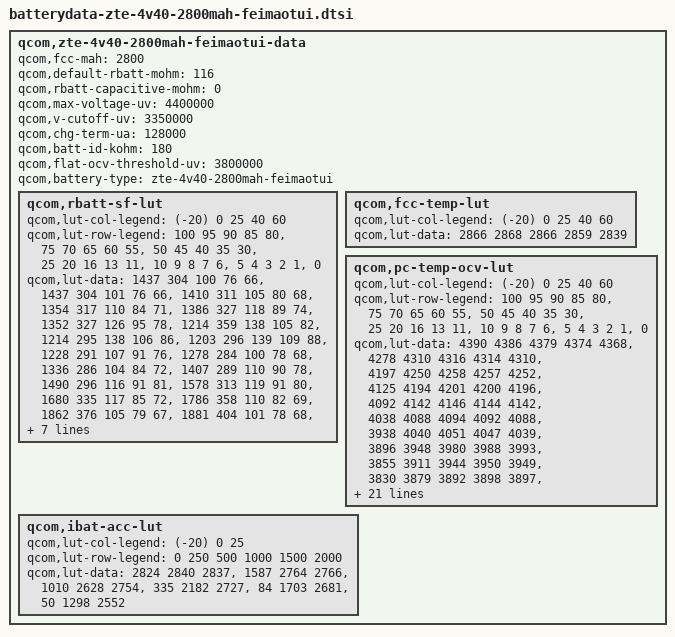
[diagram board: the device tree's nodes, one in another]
/* Copyright (c) 2014, The Linux Foundation. All rights reserved.
 *
 * This program is free software; you can redistribute it and/or modify
 * it under the terms of the GNU General Public License version 2 and
 * only version 2 as published by the Free Software Foundation.
 *
 * This program is distributed in the hope that it will be useful,
 * but WITHOUT ANY WARRANTY; without even the implied warranty of
 * MERCHANTABILITY or FITNESS FOR A PARTICULAR PURPOSE.  See the
 * GNU General Public License for more details.
 */
 qcom,zte-4v40-2800mah-feimaotui-data {
	qcom,fcc-mah = <2800>;
	qcom,default-rbatt-mohm = <116>;
	qcom,rbatt-capacitive-mohm = <0>;
	qcom,max-voltage-uv = <4400000>;
	qcom,v-cutoff-uv = <3350000>;
	qcom,chg-term-ua = <128000>;
	qcom,batt-id-kohm = <180>;
	qcom,flat-ocv-threshold-uv = <3800000>;
	qcom,battery-type = "zte-4v40-2800mah-feimaotui";
 
	qcom,rbatt-sf-lut {
		qcom,lut-col-legend = <(-20) 0 25 40 60>;
		qcom,lut-row-legend = <100 95 90 85 80>,
				<75 70 65 60 55>,
				<50 45 40 35 30>,
				<25 20 16 13 11>,
				<10 9 8 7 6>,
				<5 4 3 2 1>,
				<0>;
		qcom,lut-data = <1437 304 100 76 66>,
				<1437 304 101 76 66>,
				<1410 311 105 80 68>,
				<1354 317 110 84 71>,
				<1386 327 118 89 74>,
				<1352 327 126 95 78>,
				<1214 359 138 105 82>,
				<1214 295 138 106 86>,
				<1203 296 139 109 88>,
				<1228 291 107 91 76>,
				<1278 284 100 78 68>,
				<1336 286 104 84 72>,
				<1407 289 110 90 78>,
				<1490 296 116 91 81>,
				<1578 313 119 91 80>,
				<1680 335 117 85 72>,
				<1786 358 110 82 69>,
				<1862 376 105 79 67>,
				<1881 404 101 78 68>,
				<1815 409 107 84 72>,
				<1853 424 112 88 74>,
				<1873 445 119 91 76>,
				<1936 464 123 95 77>,
				<1989 483 126 96 75>,
				<2133 498 122 89 72>,
				<2417 509 116 87 74>,
				<2732 528 120 91 79>,
				<3215 565 128 100 84>,
				<4009 618 146 109 90>,
				<6202 741 192 133 116>,
				<36781 16819 10403 1488 6787>;
	};

	qcom,fcc-temp-lut {
		qcom,lut-col-legend = <(-20) 0 25 40 60>;
		qcom,lut-data = <2866 2868 2866 2859 2839>;
	};

	qcom,pc-temp-ocv-lut {
		qcom,lut-col-legend = <(-20) 0 25 40 60>;
		qcom,lut-row-legend = <100 95 90 85 80>,
				<75 70 65 60 55>,
				<50 45 40 35 30>,
				<25 20 16 13 11>,
				<10 9 8 7 6>,
				<5 4 3 2 1>,
				<0>;
		qcom,lut-data = <4390 4386 4379 4374 4368>,
				<4278 4310 4316 4314 4310>,
				<4197 4250 4258 4257 4252>,
				<4125 4194 4201 4200 4196>,
				<4092 4142 4146 4144 4142>,
				<4038 4088 4094 4092 4088>,
				<3938 4040 4051 4047 4039>,
				<3896 3948 3980 3988 3993>,
				<3855 3911 3944 3950 3949>,
				<3830 3879 3892 3898 3897>,
				<3812 3847 3856 3858 3858>,
				<3798 3820 3830 3832 3832>,
				<3784 3798 3808 3810 3810>,
				<3769 3781 3790 3790 3790>,
				<3754 3768 3776 3772 3769>,
				<3738 3756 3760 3753 3740>,
				<3720 3736 3738 3729 3714>,
				<3702 3716 3708 3699 3686>,
				<3684 3704 3690 3682 3670>,
				<3671 3696 3688 3680 3669>,
				<3663 3694 3688 3680 3668>,
				<3653 3691 3686 3679 3667>,
				<3642 3687 3684 3677 3664>,
				<3628 3680 3680 3672 3656>,
				<3608 3664 3663 3653 3632>,
				<3584 3635 3626 3614 3592>,
				<3547 3590 3575 3564 3542>,
				<3494 3528 3510 3501 3478>,
				<3418 3444 3424 3416 3388>,
				<3290 3312 3286 3282 3246>,
				<3000 3000 3000 3000 3000>;
	};

              /* cutof_mv 3350 */
		qcom,ibat-acc-lut {
		qcom,lut-col-legend = <(-20) 0 25>;
		qcom,lut-row-legend = <0 250 500 1000 1500 2000>;
		qcom,lut-data = <2824 2840 2837>,
					   <1587 2764 2766>,
					   <1010 2628 2754>,
				       <335 2182 2727>,
					   <84 1703 2681>,
					   <50 1298 2552>;
	};

};
